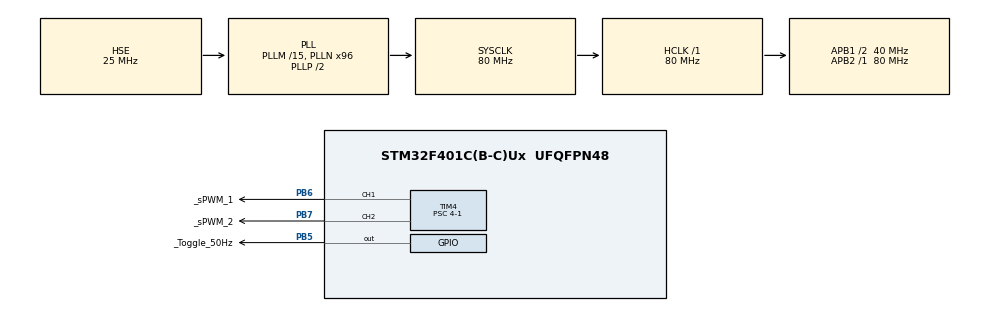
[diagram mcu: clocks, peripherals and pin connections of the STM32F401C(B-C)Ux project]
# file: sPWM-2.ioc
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Dma.Request0=TIM4_CH1
Dma.Request1=TIM4_CH2
Dma.TIM4_CH1.0.Direction=DMA_MEMORY_TO_PERIPH
Dma.TIM4_CH1.0.FIFOMode=DMA_FIFOMODE_DISABLE
Dma.TIM4_CH1.0.Instance=DMA1_Stream0
Dma.TIM4_CH1.0.MemDataAlignment=DMA_MDATAALIGN_HALFWORD
Dma.TIM4_CH1.0.MemInc=DMA_MINC_ENABLE
Dma.TIM4_CH1.0.Mode=DMA_CIRCULAR
Dma.TIM4_CH1.0.PeriphDataAlignment=DMA_PDATAALIGN_HALFWORD
Dma.TIM4_CH1.0.PeriphInc=DMA_PINC_DISABLE
Dma.TIM4_CH1.0.Priority=DMA_PRIORITY_HIGH
Dma.TIM4_CH2.1.Direction=DMA_MEMORY_TO_PERIPH
Dma.TIM4_CH2.1.FIFOMode=DMA_FIFOMODE_DISABLE
Dma.TIM4_CH2.1.Instance=DMA1_Stream3
Dma.TIM4_CH2.1.MemDataAlignment=DMA_MDATAALIGN_HALFWORD
Dma.TIM4_CH2.1.MemInc=DMA_MINC_ENABLE
Dma.TIM4_CH2.1.Mode=DMA_CIRCULAR
Dma.TIM4_CH2.1.PeriphDataAlignment=DMA_PDATAALIGN_HALFWORD
Dma.TIM4_CH2.1.PeriphInc=DMA_PINC_DISABLE
Dma.TIM4_CH2.1.Priority=DMA_PRIORITY_HIGH
Mcu.Family=STM32F4
Mcu.Name=STM32F401C(B-C)Ux
Mcu.Package=UFQFPN48
NVIC.DMA1_Stream0_IRQn=true\:0\:0\:false\:false\:true\:false\:true\:true
NVIC.DMA1_Stream3_IRQn=true\:0\:0\:false\:false\:true\:false\:true\:true
NVIC.PriorityGroup=NVIC_PRIORITYGROUP_4
PA13.Mode=Serial_Wire
PA13.Signal=SYS_JTMS-SWDIO
PA14.Mode=Serial_Wire
PA14.Signal=SYS_JTCK-SWCLK
PB5.GPIO_Label=_Toggle_50Hz
PB5.Signal=GPIO_Output
PB6.GPIO_Label=_sPWM_1
PB6.Signal=S_TIM4_CH1
PB7.GPIO_Label=_sPWM_2
PB7.Signal=S_TIM4_CH2
PH0\ -\ OSC_IN.Mode=HSE-External-Oscillator
PH0\ -\ OSC_IN.Signal=RCC_OSC_IN
PH1\ -\ OSC_OUT.Mode=HSE-External-Oscillator
PH1\ -\ OSC_OUT.Signal=RCC_OSC_OUT
ProjectManager.HeapSize=0x200
ProjectManager.StackSize=0x400
ProjectManager.TargetToolchain=STM32CubeIDE
RCC.48MHZClocksFreq_Value=40000000
RCC.AHBFreq_Value=80000000
RCC.APB1CLKDivider=RCC_HCLK_DIV2
RCC.APB1Freq_Value=40000000
RCC.APB1TimFreq_Value=80000000
RCC.APB2Freq_Value=80000000
RCC.APB2TimFreq_Value=80000000
RCC.CortexFreq_Value=80000000
RCC.HCLKFreq_Value=80000000
RCC.HSE_VALUE=25000000
RCC.HSI_VALUE=16000000
RCC.LSE_VALUE=32768
RCC.PLLM=15
RCC.PLLN=96
RCC.PLLSourceVirtual=RCC_PLLSOURCE_HSE
RCC.SYSCLKFreq_VALUE=80000000
RCC.SYSCLKSource=RCC_SYSCLKSOURCE_PLLCLK
RCC.VCOOutputFreq_Value=160000000
SH.S_TIM4_CH1.0=TIM4_CH1,PWM Generation1 CH1
SH.S_TIM4_CH2.0=TIM4_CH2,PWM Generation2 CH2
TIM4.AutoReloadPreload=TIM_AUTORELOAD_PRELOAD_ENABLE
TIM4.Channel-PWM\ Generation1\ CH1=TIM_CHANNEL_1
TIM4.Channel-PWM\ Generation2\ CH2=TIM_CHANNEL_2
TIM4.Period=1000-1
TIM4.Prescaler=4-1
VP_TIM4_VS_ClockSourceINT.Mode=Internal
board=custom

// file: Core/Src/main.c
/* USER CODE BEGIN Header */
/**
 ******************************************************************************
 * @file           : main.c
 * @brief          : Main program body
 ******************************************************************************
 * @attention
 *
 * Copyright (c) 2023 STMicroelectronics.
 * All rights reserved.
 *
 * This software is licensed under terms that can be found in the LICENSE file
 * in the root directory of this software component.
 * If no LICENSE file comes with this software, it is provided AS-IS.
 *
 ******************************************************************************
 */
/* USER CODE END Header */
#include "main.h"

/* USER CODE BEGIN PD */
#define LUT_LEN 400
/* USER CODE END PD */

TIM_HandleTypeDef htim4;
DMA_HandleTypeDef hdma_tim4_ch1;
DMA_HandleTypeDef hdma_tim4_ch2;

/* USER CODE BEGIN PV */
uint16_t sPWM_CH1_LUT[LUT_LEN] = { 0, 14, 28, 42, 57, 71, 85, 99, 113, 127, 141,
		155, 169, 183, 196, 210, 224, 237, 251, 265, 278, 292, 305, 318, 331,
		344, 357, 370, 383, 396, 409, 421, 434, 446, 458, 470, 482, 494, 506,
		518, 529, 540, 552, 563, 574, 585, 595, 606, 616, 626, 636, 646, 656,
		666, 675, 684, 693, 702, 711, 720, 728, 736, 744, 752, 760, 767, 775,
		782, 789, 795, 802, 808, 814, 820, 826, 831, 837, 842, 847, 851, 856,
		860, 864, 868, 872, 875, 878, 881, 884, 887, 889, 891, 893, 895, 896,
		897, 898, 899, 900, 900, 900, 900, 900, 899, 898, 897, 896, 895, 893,
		891, 889, 887, 884, 881, 878, 875, 872, 868, 864, 860, 856, 851, 847,
		842, 837, 831, 826, 820, 814, 808, 802, 795, 789, 782, 775, 767, 760,
		752, 744, 736, 728, 720, 711, 702, 693, 684, 675, 666, 656, 646, 636,
		626, 616, 606, 595, 585, 574, 563, 552, 540, 529, 518, 506, 494, 482,
		470, 458, 446, 434, 421, 409, 396, 383, 370, 357, 344, 331, 318, 305,
		292, 278, 265, 251, 237, 224, 210, 196, 183, 169, 155, 141, 127, 113,
		99, 85, 71, 57, 42, 28, 14, 0, 0, 0, 0, 0, 0, 0, 0, 0, 0, 0, 0, 0, 0, 0,
		0, 0, 0, 0, 0, 0, 0, 0, 0, 0, 0, 0, 0, 0, 0, 0, 0, 0, 0, 0, 0, 0, 0, 0,
		0, 0, 0, 0, 0, 0, 0, 0, 0, 0, 0, 0, 0, 0, 0, 0, 0, 0, 0, 0, 0, 0, 0, 0,
		0, 0, 0, 0, 0, 0, 0, 0, 0, 0, 0, 0, 0, 0, 0, 0, 0, 0, 0, 0, 0, 0, 0, 0,
		0, 0, 0, 0, 0, 0, 0, 0, 0, 0, 0, 0, 0, 0, 0, 0, 0, 0, 0, 0, 0, 0, 0, 0,
		0, 0, 0, 0, 0, 0, 0, 0, 0, 0, 0, 0, 0, 0, 0, 0, 0, 0, 0, 0, 0, 0, 0, 0,
		0, 0, 0, 0, 0, 0, 0, 0, 0, 0, 0, 0, 0, 0, 0, 0, 0, 0, 0, 0, 0, 0, 0, 0,
		0, 0, 0, 0, 0, 0, 0, 0, 0, 0, 0, 0, 0, 0, 0, 0, 0, 0, 0, 0, 0, 0, 0, 0,
		0, 0, 0, 0, 0, 0, 0, 0, 0, 0, 0, 0, 0, 0, 0, 0, 0 };

uint16_t sPWM_CH2_LUT[LUT_LEN] = { 0, 0, 0, 0, 0, 0, 0, 0, 0, 0, 0, 0, 0, 0, 0,
		0, 0, 0, 0, 0, 0, 0, 0, 0, 0, 0, 0, 0, 0, 0, 0, 0, 0, 0, 0, 0, 0, 0, 0,
		0, 0, 0, 0, 0, 0, 0, 0, 0, 0, 0, 0, 0, 0, 0, 0, 0, 0, 0, 0, 0, 0, 0, 0,
		0, 0, 0, 0, 0, 0, 0, 0, 0, 0, 0, 0, 0, 0, 0, 0, 0, 0, 0, 0, 0, 0, 0, 0,
		0, 0, 0, 0, 0, 0, 0, 0, 0, 0, 0, 0, 0, 0, 0, 0, 0, 0, 0, 0, 0, 0, 0, 0,
		0, 0, 0, 0, 0, 0, 0, 0, 0, 0, 0, 0, 0, 0, 0, 0, 0, 0, 0, 0, 0, 0, 0, 0,
		0, 0, 0, 0, 0, 0, 0, 0, 0, 0, 0, 0, 0, 0, 0, 0, 0, 0, 0, 0, 0, 0, 0, 0,
		0, 0, 0, 0, 0, 0, 0, 0, 0, 0, 0, 0, 0, 0, 0, 0, 0, 0, 0, 0, 0, 0, 0, 0,
		0, 0, 0, 0, 0, 0, 0, 0, 0, 0, 0, 0, 0, 0, 0, 0, 0, 0, 14, 28, 42, 57,
		71, 85, 99, 113, 127, 141, 155, 169, 183, 196, 210, 224, 237, 251, 265,
		278, 292, 305, 318, 331, 344, 357, 370, 383, 396, 409, 421, 434, 446,
		458, 470, 482, 494, 506, 518, 529, 540, 552, 563, 574, 585, 595, 606,
		616, 626, 636, 646, 656, 666, 675, 684, 693, 702, 711, 720, 728, 736,
		744, 752, 760, 767, 775, 782, 789, 795, 802, 808, 814, 820, 826, 831,
		837, 842, 847, 851, 856, 860, 864, 868, 872, 875, 878, 881, 884, 887,
		889, 891, 893, 895, 896, 897, 898, 899, 900, 900, 900, 900, 900, 899,
		898, 897, 896, 895, 893, 891, 889, 887, 884, 881, 878, 875, 872, 868,
		864, 860, 856, 851, 847, 842, 837, 831, 826, 820, 814, 808, 802, 795,
		789, 782, 775, 767, 760, 752, 744, 736, 728, 720, 711, 702, 693, 684,
		675, 666, 656, 646, 636, 626, 616, 606, 595, 585, 574, 563, 552, 540,
		529, 518, 506, 494, 482, 470, 458, 446, 434, 421, 409, 396, 383, 370,
		357, 344, 331, 318, 305, 292, 278, 265, 251, 237, 224, 210, 196, 183,
		169, 155, 141, 127, 113, 99, 85, 71, 57, 42, 28, 14 };
/* USER CODE END PV */

void SystemClock_Config(void);
static void MX_GPIO_Init(void);
static void MX_DMA_Init(void);
static void MX_TIM4_Init(void);
/* USER CODE BEGIN PFP */
void HAL_TIM_PWM_PulseFinishedHalfCpltCallback(TIM_HandleTypeDef *htim) {
	if (htim == &htim4 && htim->Channel == HAL_TIM_ACTIVE_CHANNEL_1)
		HAL_GPIO_TogglePin(GPIOB, _Toggle_50Hz_Pin);
}
void HAL_TIM_PWM_PulseFinishedCallback(TIM_HandleTypeDef *htim) {
	if (htim == &htim4 && htim->Channel == HAL_TIM_ACTIVE_CHANNEL_1)
		HAL_GPIO_TogglePin(GPIOB, _Toggle_50Hz_Pin);
}
/* USER CODE END PFP */

int main(void)
{

  /* MCU Configuration--------------------------------------------------------*/

  /* Reset of all peripherals, Initializes the Flash interface and the Systick. */
  HAL_Init();

  /* Configure the system clock */
  SystemClock_Config();

  /* Initialize all configured peripherals */
  MX_GPIO_Init();
  MX_DMA_Init();
  MX_TIM4_Init();
  /* USER CODE BEGIN 2 */
	HAL_TIM_PWM_Start_DMA(&htim4, TIM_CHANNEL_1, (uint32_t*) sPWM_CH1_LUT,
			LUT_LEN);
	HAL_TIM_PWM_Start_DMA(&htim4, TIM_CHANNEL_2, (uint32_t*) sPWM_CH2_LUT,
			LUT_LEN);
  /* USER CODE END 2 */

  /* Infinite loop */
	while (1) {

	}
}

void SystemClock_Config(void)
{
  RCC_OscInitTypeDef RCC_OscInitStruct = {0};
  RCC_ClkInitTypeDef RCC_ClkInitStruct = {0};

  /** Configure the main internal regulator output voltage
  */
  __HAL_RCC_PWR_CLK_ENABLE();
  __HAL_PWR_VOLTAGESCALING_CONFIG(PWR_REGULATOR_VOLTAGE_SCALE2);

  /** Initializes the RCC Oscillators according to the specified parameters
  * in the RCC_OscInitTypeDef structure.
  */
  RCC_OscInitStruct.OscillatorType = RCC_OSCILLATORTYPE_HSE;
  RCC_OscInitStruct.HSEState = RCC_HSE_ON;
  RCC_OscInitStruct.PLL.PLLState = RCC_PLL_ON;
  RCC_OscInitStruct.PLL.PLLSource = RCC_PLLSOURCE_HSE;
  RCC_OscInitStruct.PLL.PLLM = 15;
  RCC_OscInitStruct.PLL.PLLN = 96;
  RCC_OscInitStruct.PLL.PLLP = RCC_PLLP_DIV2;
  RCC_OscInitStruct.PLL.PLLQ = 4;
  if (HAL_RCC_OscConfig(&RCC_OscInitStruct) != HAL_OK)
  {
    Error_Handler();
  }

  /** Initializes the CPU, AHB and APB buses clocks
  */
  RCC_ClkInitStruct.ClockType = RCC_CLOCKTYPE_HCLK|RCC_CLOCKTYPE_SYSCLK
                              |RCC_CLOCKTYPE_PCLK1|RCC_CLOCKTYPE_PCLK2;
  RCC_ClkInitStruct.SYSCLKSource = RCC_SYSCLKSOURCE_PLLCLK;
  RCC_ClkInitStruct.AHBCLKDivider = RCC_SYSCLK_DIV1;
  RCC_ClkInitStruct.APB1CLKDivider = RCC_HCLK_DIV2;
  RCC_ClkInitStruct.APB2CLKDivider = RCC_HCLK_DIV1;

  if (HAL_RCC_ClockConfig(&RCC_ClkInitStruct, FLASH_LATENCY_2) != HAL_OK)
  {
    Error_Handler();
  }
}

static void MX_TIM4_Init(void)
{

  TIM_ClockConfigTypeDef sClockSourceConfig = {0};
  TIM_MasterConfigTypeDef sMasterConfig = {0};
  TIM_OC_InitTypeDef sConfigOC = {0};

  htim4.Instance = TIM4;
  htim4.Init.Prescaler = 4-1;
  htim4.Init.CounterMode = TIM_COUNTERMODE_UP;
  htim4.Init.Period = 1000-1;
  htim4.Init.ClockDivision = TIM_CLOCKDIVISION_DIV1;
  htim4.Init.AutoReloadPreload = TIM_AUTORELOAD_PRELOAD_ENABLE;
  if (HAL_TIM_Base_Init(&htim4) != HAL_OK)
  {
    Error_Handler();
  }
  sClockSourceConfig.ClockSource = TIM_CLOCKSOURCE_INTERNAL;
  if (HAL_TIM_ConfigClockSource(&htim4, &sClockSourceConfig) != HAL_OK)
  {
    Error_Handler();
  }
  if (HAL_TIM_PWM_Init(&htim4) != HAL_OK)
  {
    Error_Handler();
  }
  sMasterConfig.MasterOutputTrigger = TIM_TRGO_RESET;
  sMasterConfig.MasterSlaveMode = TIM_MASTERSLAVEMODE_DISABLE;
  if (HAL_TIMEx_MasterConfigSynchronization(&htim4, &sMasterConfig) != HAL_OK)
  {
    Error_Handler();
  }
  sConfigOC.OCMode = TIM_OCMODE_PWM1;
  sConfigOC.Pulse = 0;
  sConfigOC.OCPolarity = TIM_OCPOLARITY_HIGH;
  sConfigOC.OCFastMode = TIM_OCFAST_DISABLE;
  if (HAL_TIM_PWM_ConfigChannel(&htim4, &sConfigOC, TIM_CHANNEL_1) != HAL_OK)
  {
    Error_Handler();
  }
  if (HAL_TIM_PWM_ConfigChannel(&htim4, &sConfigOC, TIM_CHANNEL_2) != HAL_OK)
  {
    Error_Handler();
  }
  HAL_TIM_MspPostInit(&htim4);

}

static void MX_DMA_Init(void)
{

  /* DMA controller clock enable */
  __HAL_RCC_DMA1_CLK_ENABLE();

  /* DMA interrupt init */
  /* DMA1_Stream0_IRQn interrupt configuration */
  HAL_NVIC_SetPriority(DMA1_Stream0_IRQn, 0, 0);
  HAL_NVIC_EnableIRQ(DMA1_Stream0_IRQn);
  /* DMA1_Stream3_IRQn interrupt configuration */
  HAL_NVIC_SetPriority(DMA1_Stream3_IRQn, 0, 0);
  HAL_NVIC_EnableIRQ(DMA1_Stream3_IRQn);

}

static void MX_GPIO_Init(void)
{
  GPIO_InitTypeDef GPIO_InitStruct = {0};

  /* GPIO Ports Clock Enable */
  __HAL_RCC_GPIOH_CLK_ENABLE();
  __HAL_RCC_GPIOA_CLK_ENABLE();
  __HAL_RCC_GPIOB_CLK_ENABLE();

  /*Configure GPIO pin Output Level */
  HAL_GPIO_WritePin(_Toggle_50Hz_GPIO_Port, _Toggle_50Hz_Pin, GPIO_PIN_RESET);

  /*Configure GPIO pin : _Toggle_50Hz_Pin */
  GPIO_InitStruct.Pin = _Toggle_50Hz_Pin;
  GPIO_InitStruct.Mode = GPIO_MODE_OUTPUT_PP;
  GPIO_InitStruct.Pull = GPIO_NOPULL;
  GPIO_InitStruct.Speed = GPIO_SPEED_FREQ_LOW;
  HAL_GPIO_Init(_Toggle_50Hz_GPIO_Port, &GPIO_InitStruct);

}

void Error_Handler(void)
{
	__disable_irq();
	while (1) {
	}
}
